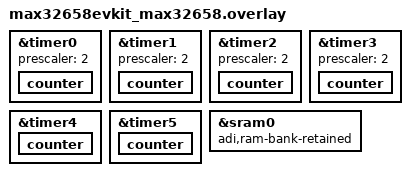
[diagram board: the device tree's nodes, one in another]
/*
 * Copyright (c) 2026 Analog Devices, Inc.
 *
 * SPDX-License-Identifier: Apache-2.0
 */

&timer0 {
	prescaler = <2>;
	status = "okay";

	counter {
		status = "okay";
	};
};

&timer1 {
	prescaler = <2>;
	status = "okay";

	counter {
		status = "okay";
	};
};

&timer2 {
	prescaler = <2>;
	status = "okay";

	counter {
		status = "okay";
	};
};

&timer3 {
	prescaler = <2>;
	status = "okay";

	counter {
		status = "okay";
	};
};

&timer4 {
	status = "okay";

	counter {
		status = "okay";
	};
};

&timer5 {
	status = "okay";

	counter {
		status = "okay";
	};
};

/*
 * SRAM banks marked with the following property are retained in backup mode
 *
 * SRAM banks are listed in max32657_common.dtsi
 */
&sram0 {
	adi,ram-bank-retained;
};
